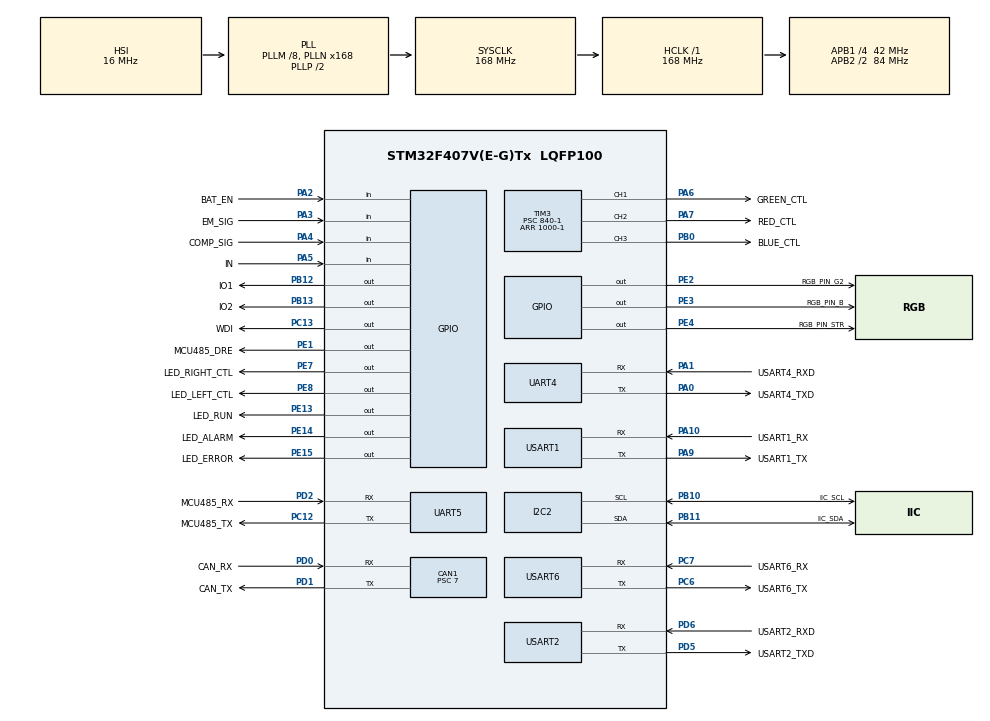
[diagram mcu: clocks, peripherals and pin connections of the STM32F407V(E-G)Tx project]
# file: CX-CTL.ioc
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CAN1.BS1=CAN_BS1_9TQ
CAN1.BS2=CAN_BS2_2TQ
CAN1.CalculateBaudRate=499999
CAN1.CalculateTimeBit=2000
CAN1.CalculateTimeQuantum=166.66666666666669
CAN1.Prescaler=7
Dma.Request0=UART4_TX
Dma.Request1=UART4_RX
Dma.Request2=UART5_RX
Dma.Request3=UART5_TX
Dma.Request4=USART1_RX
Dma.Request5=USART1_TX
Dma.Request6=USART2_RX
Dma.Request7=USART2_TX
Dma.Request8=USART6_RX
Dma.Request9=USART6_TX
Dma.UART4_RX.1.Direction=DMA_PERIPH_TO_MEMORY
Dma.UART4_RX.1.FIFOMode=DMA_FIFOMODE_DISABLE
Dma.UART4_RX.1.Instance=DMA1_Stream2
Dma.UART4_RX.1.MemDataAlignment=DMA_MDATAALIGN_BYTE
Dma.UART4_RX.1.MemInc=DMA_MINC_ENABLE
Dma.UART4_RX.1.Mode=DMA_NORMAL
Dma.UART4_RX.1.PeriphDataAlignment=DMA_PDATAALIGN_BYTE
Dma.UART4_RX.1.PeriphInc=DMA_PINC_DISABLE
Dma.UART4_RX.1.Priority=DMA_PRIORITY_LOW
Dma.UART4_TX.0.Direction=DMA_MEMORY_TO_PERIPH
Dma.UART4_TX.0.FIFOMode=DMA_FIFOMODE_DISABLE
Dma.UART4_TX.0.Instance=DMA1_Stream4
Dma.UART4_TX.0.MemDataAlignment=DMA_MDATAALIGN_BYTE
Dma.UART4_TX.0.MemInc=DMA_MINC_ENABLE
Dma.UART4_TX.0.Mode=DMA_NORMAL
Dma.UART4_TX.0.PeriphDataAlignment=DMA_PDATAALIGN_BYTE
Dma.UART4_TX.0.PeriphInc=DMA_PINC_DISABLE
Dma.UART4_TX.0.Priority=DMA_PRIORITY_LOW
Dma.UART5_RX.2.Direction=DMA_PERIPH_TO_MEMORY
Dma.UART5_RX.2.FIFOMode=DMA_FIFOMODE_DISABLE
Dma.UART5_RX.2.Instance=DMA1_Stream0
Dma.UART5_RX.2.MemDataAlignment=DMA_MDATAALIGN_BYTE
Dma.UART5_RX.2.MemInc=DMA_MINC_ENABLE
Dma.UART5_RX.2.Mode=DMA_NORMAL
Dma.UART5_RX.2.PeriphDataAlignment=DMA_PDATAALIGN_BYTE
Dma.UART5_RX.2.PeriphInc=DMA_PINC_DISABLE
Dma.UART5_RX.2.Priority=DMA_PRIORITY_LOW
Dma.UART5_TX.3.Direction=DMA_MEMORY_TO_PERIPH
Dma.UART5_TX.3.FIFOMode=DMA_FIFOMODE_DISABLE
Dma.UART5_TX.3.Instance=DMA1_Stream7
Dma.UART5_TX.3.MemDataAlignment=DMA_MDATAALIGN_BYTE
Dma.UART5_TX.3.MemInc=DMA_MINC_ENABLE
Dma.UART5_TX.3.Mode=DMA_NORMAL
Dma.UART5_TX.3.PeriphDataAlignment=DMA_PDATAALIGN_BYTE
Dma.UART5_TX.3.PeriphInc=DMA_PINC_DISABLE
Dma.UART5_TX.3.Priority=DMA_PRIORITY_LOW
Dma.USART1_RX.4.Direction=DMA_PERIPH_TO_MEMORY
Dma.USART1_RX.4.FIFOMode=DMA_FIFOMODE_DISABLE
Dma.USART1_RX.4.Instance=DMA2_Stream2
Dma.USART1_RX.4.MemDataAlignment=DMA_MDATAALIGN_BYTE
Dma.USART1_RX.4.MemInc=DMA_MINC_ENABLE
Dma.USART1_RX.4.Mode=DMA_NORMAL
Dma.USART1_RX.4.PeriphDataAlignment=DMA_PDATAALIGN_BYTE
Dma.USART1_RX.4.PeriphInc=DMA_PINC_DISABLE
Dma.USART1_RX.4.Priority=DMA_PRIORITY_LOW
Dma.USART1_TX.5.Direction=DMA_MEMORY_TO_PERIPH
Dma.USART1_TX.5.FIFOMode=DMA_FIFOMODE_DISABLE
Dma.USART1_TX.5.Instance=DMA2_Stream7
Dma.USART1_TX.5.MemDataAlignment=DMA_MDATAALIGN_BYTE
Dma.USART1_TX.5.MemInc=DMA_MINC_ENABLE
Dma.USART1_TX.5.Mode=DMA_NORMAL
Dma.USART1_TX.5.PeriphDataAlignment=DMA_PDATAALIGN_BYTE
Dma.USART1_TX.5.PeriphInc=DMA_PINC_DISABLE
Dma.USART1_TX.5.Priority=DMA_PRIORITY_LOW
Dma.USART2_RX.6.Direction=DMA_PERIPH_TO_MEMORY
Dma.USART2_RX.6.FIFOMode=DMA_FIFOMODE_DISABLE
Dma.USART2_RX.6.Instance=DMA1_Stream5
Dma.USART2_RX.6.MemDataAlignment=DMA_MDATAALIGN_BYTE
Dma.USART2_RX.6.MemInc=DMA_MINC_ENABLE
Dma.USART2_RX.6.Mode=DMA_NORMAL
Dma.USART2_RX.6.PeriphDataAlignment=DMA_PDATAALIGN_BYTE
Dma.USART2_RX.6.PeriphInc=DMA_PINC_DISABLE
Dma.USART2_RX.6.Priority=DMA_PRIORITY_LOW
Dma.USART2_TX.7.Direction=DMA_MEMORY_TO_PERIPH
Dma.USART2_TX.7.FIFOMode=DMA_FIFOMODE_DISABLE
Dma.USART2_TX.7.Instance=DMA1_Stream6
Dma.USART2_TX.7.MemDataAlignment=DMA_MDATAALIGN_BYTE
Dma.USART2_TX.7.MemInc=DMA_MINC_ENABLE
Dma.USART2_TX.7.Mode=DMA_NORMAL
Dma.USART2_TX.7.PeriphDataAlignment=DMA_PDATAALIGN_BYTE
Dma.USART2_TX.7.PeriphInc=DMA_PINC_DISABLE
Dma.USART2_TX.7.Priority=DMA_PRIORITY_LOW
Dma.USART6_RX.8.Direction=DMA_PERIPH_TO_MEMORY
Dma.USART6_RX.8.FIFOMode=DMA_FIFOMODE_DISABLE
Dma.USART6_RX.8.Instance=DMA2_Stream1
Dma.USART6_RX.8.MemDataAlignment=DMA_MDATAALIGN_BYTE
Dma.USART6_RX.8.MemInc=DMA_MINC_ENABLE
Dma.USART6_RX.8.Mode=DMA_NORMAL
Dma.USART6_RX.8.PeriphDataAlignment=DMA_PDATAALIGN_BYTE
Dma.USART6_RX.8.PeriphInc=DMA_PINC_DISABLE
Dma.USART6_RX.8.Priority=DMA_PRIORITY_LOW
Dma.USART6_TX.9.Direction=DMA_MEMORY_TO_PERIPH
Dma.USART6_TX.9.FIFOMode=DMA_FIFOMODE_DISABLE
Dma.USART6_TX.9.Instance=DMA2_Stream6
Dma.USART6_TX.9.MemDataAlignment=DMA_MDATAALIGN_BYTE
Dma.USART6_TX.9.MemInc=DMA_MINC_ENABLE
Dma.USART6_TX.9.Mode=DMA_NORMAL
Dma.USART6_TX.9.PeriphDataAlignment=DMA_PDATAALIGN_BYTE
Dma.USART6_TX.9.PeriphInc=DMA_PINC_DISABLE
Dma.USART6_TX.9.Priority=DMA_PRIORITY_LOW
FREERTOS.Mutexes01=AppPrintfMutex,Dynamic,NULL;AppVelocityMutex,Dynamic,NULL
FREERTOS.Queues01=RS485TxQueue,10,uint32_t,0,Dynamic,NULL,NULL;RS485RxQueue,10,uint32_t,0,Dynamic,NULL,NULL;USART1TxQueue,10,uint32_t,0,Dynamic,NULL,NULL;USART1RxQueue,10,uint32_t,0,Dynamic,NULL,NULL;USART2TxQueue,10,uint32_t,0,Dynamic,NULL,NULL;USART4TxQueue,10,uint32_t,0,Dynamic,NULL,NULL;USART4RxQueue,10,uint32_t,0,Dynamic,NULL,NULL;USART6TxQueue,10,uint32_t,0,Dynamic,NULL,NULL;USART6RxQueue,10,uint32_t,0,Dynamic,NULL,NULL;USART2RxQueue,10,uint32_t,0,Dynamic,NULL,NULL;CAN1TxQueue,10,uint32_t,0,Dynamic,NULL,NULL
FREERTOS.Tasks01=TaskSysInit,40,512,StartTaskSYSInit,As weak,NULL,Dynamic,NULL,NULL;ledTask,24,128,StartTaskLed,As weak,NULL,Dynamic,NULL,NULL;canTask,40,512,StartTaskCan,As weak,NULL,Dynamic,NULL,NULL;watchdogTask,24,128,StartTaskWatchdog,As weak,NULL,Dynamic,NULL,NULL;rs232Task,24,128,StartTaskRS232,As weak,NULL,Dynamic,NULL,NULL;rs485Task,24,128,StartTaskRS485,As weak,NULL,Dynamic,NULL,NULL;serialTask,24,128,StartTaskSerial,As weak,NULL,Dynamic,NULL,NULL;motionTask,48,512,StartTaskMotion,As weak,NULL,Dynamic,NULL,NULL
Mcu.Family=STM32F4
Mcu.Name=STM32F407V(E-G)Tx
Mcu.Package=LQFP100
NVIC.CAN1_RX0_IRQn=true\:5\:0\:false\:false\:true\:true\:true\:true\:true
NVIC.DMA1_Stream0_IRQn=true\:5\:0\:false\:false\:true\:true\:false\:true\:true
NVIC.DMA1_Stream2_IRQn=true\:5\:0\:false\:false\:true\:true\:false\:true\:true
NVIC.DMA1_Stream4_IRQn=true\:5\:0\:false\:false\:true\:true\:false\:true\:true
NVIC.DMA1_Stream5_IRQn=true\:5\:0\:false\:false\:true\:true\:false\:true\:true
NVIC.DMA1_Stream6_IRQn=true\:5\:0\:false\:false\:true\:true\:false\:true\:true
NVIC.DMA1_Stream7_IRQn=true\:5\:0\:false\:false\:true\:true\:false\:true\:true
NVIC.DMA2_Stream1_IRQn=true\:5\:0\:false\:false\:true\:true\:false\:true\:true
NVIC.DMA2_Stream2_IRQn=true\:5\:0\:false\:false\:true\:true\:false\:true\:true
NVIC.DMA2_Stream6_IRQn=true\:5\:0\:false\:false\:true\:true\:false\:true\:true
NVIC.DMA2_Stream7_IRQn=true\:5\:0\:false\:false\:true\:true\:false\:true\:true
NVIC.I2C2_ER_IRQn=true\:5\:0\:false\:false\:true\:true\:true\:true\:true
NVIC.I2C2_EV_IRQn=true\:5\:0\:false\:false\:true\:true\:true\:true\:true
NVIC.PriorityGroup=NVIC_PRIORITYGROUP_4
NVIC.TIM2_IRQn=true\:5\:0\:false\:false\:true\:true\:true\:true\:true
NVIC.TIM3_IRQn=true\:5\:0\:false\:false\:true\:true\:true\:true\:true
NVIC.TIM4_IRQn=true\:5\:0\:false\:false\:true\:true\:true\:true\:true
NVIC.TIM5_IRQn=true\:5\:0\:false\:false\:true\:true\:true\:true\:true
NVIC.UART4_IRQn=true\:5\:0\:false\:false\:true\:true\:true\:true\:true
NVIC.UART5_IRQn=true\:5\:0\:false\:false\:true\:true\:true\:true\:true
NVIC.USART1_IRQn=true\:5\:0\:false\:false\:true\:true\:true\:true\:true
NVIC.USART2_IRQn=true\:5\:0\:false\:false\:true\:true\:true\:true\:true
NVIC.USART6_IRQn=true\:5\:0\:false\:false\:true\:true\:true\:true\:true
PA0-WKUP.GPIO_Label=USART4_TXD
PA0-WKUP.GPIO_PuPd=GPIO_PULLUP
PA0-WKUP.Mode=Asynchronous
PA0-WKUP.Signal=UART4_TX
PA1.GPIO_Label=USART4_RXD
PA1.GPIO_PuPd=GPIO_PULLUP
PA1.Mode=Asynchronous
PA1.Signal=UART4_RX
PA10.GPIO_Label=USART1_RX
PA10.GPIO_PuPd=GPIO_PULLUP
PA10.Mode=Asynchronous
PA10.Signal=USART1_RX
PA13.GPIO_Label=SWDIO
PA13.Mode=Serial_Wire
PA13.Signal=SYS_JTMS-SWDIO
PA14.GPIO_Label=SWCLK
PA14.Mode=Serial_Wire
PA14.Signal=SYS_JTCK-SWCLK
PA2.GPIO_Label=BAT_EN
PA2.GPIO_PuPd=GPIO_PULLUP
PA2.Signal=GPIO_Input
PA3.GPIO_Label=EM_SIG
PA3.GPIO_PuPd=GPIO_PULLUP
PA3.Signal=GPIO_Input
PA4.GPIO_Label=COMP_SIG
PA4.GPIO_PuPd=GPIO_PULLUP
PA4.Signal=GPIO_Input
PA5.GPIO_Label=IN
PA5.GPIO_PuPd=GPIO_PULLUP
PA5.Signal=GPIO_Input
PA6.GPIO_Label=GREEN_CTL
PA6.GPIO_PuPd=GPIO_PULLUP
PA6.Signal=S_TIM3_CH1
PA7.GPIO_Label=RED_CTL
PA7.GPIO_PuPd=GPIO_PULLUP
PA7.Signal=S_TIM3_CH2
PA9.GPIO_Label=USART1_TX
PA9.GPIO_PuPd=GPIO_PULLUP
PA9.Mode=Asynchronous
PA9.Signal=USART1_TX
PB0.GPIO_Label=BLUE_CTL
PB0.GPIO_PuPd=GPIO_PULLUP
PB0.Signal=S_TIM3_CH3
PB10.GPIO_Label=IIC_SCL
PB10.GPIO_Pu=GPIO_PULLUP
PB10.Mode=I2C
PB10.Signal=I2C2_SCL
PB11.GPIO_Label=IIC_SDA
PB11.GPIO_Pu=GPIO_PULLUP
PB11.Mode=I2C
PB11.Signal=I2C2_SDA
PB12.GPIO_Label=IO1
PB12.GPIO_Speed=GPIO_SPEED_FREQ_VERY_HIGH
PB12.Signal=GPIO_Output
PB13.GPIO_Label=IO2
PB13.GPIO_Speed=GPIO_SPEED_FREQ_VERY_HIGH
PB13.Signal=GPIO_Output
PC12.GPIO_Label=MCU485_TX
PC12.GPIO_PuPd=GPIO_PULLUP
PC12.Mode=Asynchronous
PC12.Signal=UART5_TX
PC13-ANTI_TAMP.GPIO_Label=WDI
PC13-ANTI_TAMP.GPIO_PuPd=GPIO_PULLUP
PC13-ANTI_TAMP.Signal=GPIO_Output
PC6.GPIO_Label=USART6_TX
PC6.GPIO_PuPd=GPIO_PULLUP
PC6.Mode=Asynchronous
PC6.Signal=USART6_TX
PC7.GPIO_Label=USART6_RX
PC7.GPIO_PuPd=GPIO_PULLUP
PC7.Mode=Asynchronous
PC7.Signal=USART6_RX
PD0.GPIO_Label=CAN_RX
PD0.GPIO_PuPd=GPIO_PULLUP
PD0.Mode=CAN_Activate
PD0.Signal=CAN1_RX
PD1.GPIO_Label=CAN_TX
PD1.GPIO_PuPd=GPIO_PULLUP
PD1.Mode=CAN_Activate
PD1.Signal=CAN1_TX
PD2.GPIO_Label=MCU485_RX
PD2.GPIO_PuPd=GPIO_PULLUP
PD2.Mode=Asynchronous
PD2.Signal=UART5_RX
PD5.GPIO_Label=USART2_TXD
PD5.GPIO_PuPd=GPIO_PULLUP
PD5.Mode=Asynchronous
PD5.Signal=USART2_TX
PD6.GPIO_Label=USART2_RXD
PD6.GPIO_PuPd=GPIO_PULLUP
PD6.Mode=Asynchronous
PD6.Signal=USART2_RX
PE1.GPIO_Label=MCU485_DRE
PE1.GPIO_PuPd=GPIO_PULLUP
PE1.GPIO_Speed=GPIO_SPEED_FREQ_VERY_HIGH
PE1.Signal=GPIO_Output
PE13.GPIO_Label=LED_RUN
PE13.GPIO_PuPd=GPIO_PULLUP
PE13.GPIO_Speed=GPIO_SPEED_FREQ_VERY_HIGH
PE13.Signal=GPIO_Output
PE14.GPIO_Label=LED_ALARM
PE14.GPIO_PuPd=GPIO_PULLUP
PE14.GPIO_Speed=GPIO_SPEED_FREQ_VERY_HIGH
PE14.Signal=GPIO_Output
PE15.GPIO_Label=LED_ERROR
PE15.GPIO_PuPd=GPIO_PULLUP
PE15.GPIO_Speed=GPIO_SPEED_FREQ_VERY_HIGH
PE15.Signal=GPIO_Output
PE2.GPIO_Label=RGB_PIN_G2
PE2.GPIO_PuPd=GPIO_PULLUP
PE2.GPIO_Speed=GPIO_SPEED_FREQ_VERY_HIGH
PE2.Signal=GPIO_Output
PE3.GPIO_Label=RGB_PIN_B
PE3.GPIO_PuPd=GPIO_PULLUP
PE3.GPIO_Speed=GPIO_SPEED_FREQ_VERY_HIGH
PE3.Signal=GPIO_Output
PE4.GPIO_Label=RGB_PIN_STR
PE4.GPIO_PuPd=GPIO_PULLUP
PE4.GPIO_Speed=GPIO_SPEED_FREQ_VERY_HIGH
PE4.Signal=GPIO_Output
PE7.GPIO_Label=LED_RIGHT_CTL
PE7.GPIO_Speed=GPIO_SPEED_FREQ_VERY_HIGH
PE7.Signal=GPIO_Output
PE8.GPIO_Label=LED_LEFT_CTL
PE8.GPIO_PuPd=GPIO_PULLUP
PE8.GPIO_Speed=GPIO_SPEED_FREQ_VERY_HIGH
PE8.Signal=GPIO_Output
PH0-OSC_IN.Mode=HSE-External-Oscillator
PH0-OSC_IN.Signal=RCC_OSC_IN
PH1-OSC_OUT.Mode=HSE-External-Oscillator
PH1-OSC_OUT.Signal=RCC_OSC_OUT
ProjectManager.HeapSize=0x200
ProjectManager.StackSize=0x400
ProjectManager.TargetToolchain=MDK-ARM V5.32
RCC.48MHZClocksFreq_Value=84000000
RCC.AHBFreq_Value=168000000
RCC.APB1CLKDivider=RCC_HCLK_DIV4
RCC.APB1Freq_Value=42000000
RCC.APB1TimFreq_Value=84000000
RCC.APB2CLKDivider=RCC_HCLK_DIV2
RCC.APB2Freq_Value=84000000
RCC.APB2TimFreq_Value=168000000
RCC.CortexFreq_Value=168000000
RCC.HCLKFreq_Value=168000000
RCC.HSE_VALUE=8000000
RCC.HSI_VALUE=16000000
RCC.LSE_VALUE=32768
RCC.PLLM=8
RCC.PLLN=168
RCC.SYSCLKFreq_VALUE=168000000
RCC.SYSCLKSource=RCC_SYSCLKSOURCE_PLLCLK
RCC.VCOOutputFreq_Value=336000000
SH.S_TIM3_CH1.0=TIM3_CH1,PWM Generation1 CH1
SH.S_TIM3_CH2.0=TIM3_CH2,PWM Generation2 CH2
SH.S_TIM3_CH3.0=TIM3_CH3,PWM Generation3 CH3
TIM2.Period=50
TIM2.Prescaler=8400-1
TIM3.Channel-PWM\ Generation1\ CH1=TIM_CHANNEL_1
TIM3.Channel-PWM\ Generation2\ CH2=TIM_CHANNEL_2
TIM3.Channel-PWM\ Generation3\ CH3=TIM_CHANNEL_3
TIM3.Period=1000-1
TIM3.Prescaler=840-1
TIM4.Channel-Output\ Compare1\ No\ Output=TIM_CHANNEL_1
TIM4.Period=1000-1
TIM4.Prescaler=84-1
TIM5.Period=1000
TIM5.Prescaler=840-1
UART4.VirtualMode=Asynchronous
UART5.VirtualMode=Asynchronous
USART1.VirtualMode=VM_ASYNC
USART2.VirtualMode=VM_ASYNC
USART6.VirtualMode=VM_ASYNC
VP_FREERTOS_VS_CMSIS_V2.Mode=CMSIS_V2
VP_TIM2_VS_ClockSourceINT.Mode=Internal
VP_TIM3_VS_ClockSourceINT.Mode=Internal
VP_TIM4_VS_no_output1.Mode=Output Compare1 No Output
VP_TIM5_VS_ClockSourceINT.Mode=Internal
board=custom

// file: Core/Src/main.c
/* USER CODE BEGIN Header */
/**
  ******************************************************************************
  * @file           : main.c
  * @brief          : Main program body
  ******************************************************************************
  * @attention
  *
  * Copyright (c) 2022 STMicroelectronics.
  * All rights reserved.
  *
  * This software is licensed under terms that can be found in the LICENSE file
  * in the root directory of this software component.
  * If no LICENSE file comes with this software, it is provided AS-IS.
  *
  ******************************************************************************
  */
/* USER CODE END Header */
#include "main.h"
#include "cmsis_os.h"
#include "can.h"
#include "dma.h"
#include "i2c.h"
#include "tim.h"
#include "usart.h"
#include "gpio.h"

void SystemClock_Config(void);
void MX_FREERTOS_Init(void);

int main(void)
{

  /* MCU Configuration--------------------------------------------------------*/

  /* Reset of all peripherals, Initializes the Flash interface and the Systick. */
  HAL_Init();

  /* Configure the system clock */
  SystemClock_Config();

  /* Initialize all configured peripherals */
  MX_GPIO_Init();
  MX_DMA_Init();
  MX_CAN1_Init();
  MX_I2C2_Init();
  MX_TIM2_Init();
  MX_TIM3_Init();
  MX_TIM4_Init();
  MX_TIM5_Init();
  MX_UART4_Init();
  MX_UART5_Init();
  MX_USART1_UART_Init();
  MX_USART2_UART_Init();
  MX_USART6_UART_Init();

  /* Init scheduler */
  osKernelInitialize();  /* Call init function for freertos objects (in freertos.c) */
  MX_FREERTOS_Init();

  /* Start scheduler */
  osKernelStart();

  /* We should never get here as control is now taken by the scheduler */
  /* Infinite loop */
  while (1)
  {

  }
}

void SystemClock_Config(void)
{
  RCC_OscInitTypeDef RCC_OscInitStruct = {0};
  RCC_ClkInitTypeDef RCC_ClkInitStruct = {0};

  /** Configure the main internal regulator output voltage
  */
  __HAL_RCC_PWR_CLK_ENABLE();
  __HAL_PWR_VOLTAGESCALING_CONFIG(PWR_REGULATOR_VOLTAGE_SCALE1);

  /** Initializes the RCC Oscillators according to the specified parameters
  * in the RCC_OscInitTypeDef structure.
  */
  RCC_OscInitStruct.OscillatorType = RCC_OSCILLATORTYPE_HSI;
  RCC_OscInitStruct.HSIState = RCC_HSI_ON;
  RCC_OscInitStruct.HSICalibrationValue = RCC_HSICALIBRATION_DEFAULT;
  RCC_OscInitStruct.PLL.PLLState = RCC_PLL_ON;
  RCC_OscInitStruct.PLL.PLLSource = RCC_PLLSOURCE_HSI;
  RCC_OscInitStruct.PLL.PLLM = 8;
  RCC_OscInitStruct.PLL.PLLN = 168;
  RCC_OscInitStruct.PLL.PLLP = RCC_PLLP_DIV2;
  RCC_OscInitStruct.PLL.PLLQ = 4;
  if (HAL_RCC_OscConfig(&RCC_OscInitStruct) != HAL_OK)
  {
    Error_Handler();
  }

  /** Initializes the CPU, AHB and APB buses clocks
  */
  RCC_ClkInitStruct.ClockType = RCC_CLOCKTYPE_HCLK|RCC_CLOCKTYPE_SYSCLK
                              |RCC_CLOCKTYPE_PCLK1|RCC_CLOCKTYPE_PCLK2;
  RCC_ClkInitStruct.SYSCLKSource = RCC_SYSCLKSOURCE_PLLCLK;
  RCC_ClkInitStruct.AHBCLKDivider = RCC_SYSCLK_DIV1;
  RCC_ClkInitStruct.APB1CLKDivider = RCC_HCLK_DIV4;
  RCC_ClkInitStruct.APB2CLKDivider = RCC_HCLK_DIV2;

  if (HAL_RCC_ClockConfig(&RCC_ClkInitStruct, FLASH_LATENCY_5) != HAL_OK)
  {
    Error_Handler();
  }
}

void Error_Handler(void)
{
  __disable_irq();
  while (1)
  {
  }
}

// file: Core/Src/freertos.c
/* USER CODE BEGIN Header */
/**
  ******************************************************************************
  * File Name          : freertos.c
  * Description        : Code for freertos applications
  ******************************************************************************
  * @attention
  *
  * Copyright (c) 2022 STMicroelectronics.
  * All rights reserved.
  *
  * This software is licensed under terms that can be found in the LICENSE file
  * in the root directory of this software component.
  * If no LICENSE file comes with this software, it is provided AS-IS.
  *
  ******************************************************************************
  */
/* USER CODE END Header */

#include "FreeRTOS.h"
#include "task.h"
#include "main.h"
#include "cmsis_os.h"

/* USER CODE BEGIN Variables */
volatile unsigned long ulHighFrequencyTimerTicks;
/* USER CODE END Variables */
/* Definitions for TaskSysInit */
osThreadId_t TaskSysInitHandle;
const osThreadAttr_t TaskSysInit_attributes = {
  .name = "TaskSysInit",
  .stack_size = 512 * 4,
  .priority = (osPriority_t) osPriorityHigh,
};
/* Definitions for ledTask */
osThreadId_t ledTaskHandle;
const osThreadAttr_t ledTask_attributes = {
  .name = "ledTask",
  .stack_size = 128 * 4,
  .priority = (osPriority_t) osPriorityNormal,
};
/* Definitions for canTask */
osThreadId_t canTaskHandle;
const osThreadAttr_t canTask_attributes = {
  .name = "canTask",
  .stack_size = 512 * 4,
  .priority = (osPriority_t) osPriorityHigh,
};
/* Definitions for watchdogTask */
osThreadId_t watchdogTaskHandle;
const osThreadAttr_t watchdogTask_attributes = {
  .name = "watchdogTask",
  .stack_size = 128 * 4,
  .priority = (osPriority_t) osPriorityNormal,
};
/* Definitions for rs232Task */
osThreadId_t rs232TaskHandle;
const osThreadAttr_t rs232Task_attributes = {
  .name = "rs232Task",
  .stack_size = 128 * 4,
  .priority = (osPriority_t) osPriorityNormal,
};
/* Definitions for rs485Task */
osThreadId_t rs485TaskHandle;
const osThreadAttr_t rs485Task_attributes = {
  .name = "rs485Task",
  .stack_size = 128 * 4,
  .priority = (osPriority_t) osPriorityNormal,
};
/* Definitions for serialTask */
osThreadId_t serialTaskHandle;
const osThreadAttr_t serialTask_attributes = {
  .name = "serialTask",
  .stack_size = 128 * 4,
  .priority = (osPriority_t) osPriorityNormal,
};
/* Definitions for motionTask */
osThreadId_t motionTaskHandle;
const osThreadAttr_t motionTask_attributes = {
  .name = "motionTask",
  .stack_size = 512 * 4,
  .priority = (osPriority_t) osPriorityRealtime,
};
/* Definitions for RS485TxQueue */
osMessageQueueId_t RS485TxQueueHandle;
const osMessageQueueAttr_t RS485TxQueue_attributes = {
  .name = "RS485TxQueue"
};
/* Definitions for RS485RxQueue */
osMessageQueueId_t RS485RxQueueHandle;
const osMessageQueueAttr_t RS485RxQueue_attributes = {
  .name = "RS485RxQueue"
};
/* Definitions for USART1TxQueue */
osMessageQueueId_t USART1TxQueueHandle;
const osMessageQueueAttr_t USART1TxQueue_attributes = {
  .name = "USART1TxQueue"
};
/* Definitions for USART1RxQueue */
osMessageQueueId_t USART1RxQueueHandle;
const osMessageQueueAttr_t USART1RxQueue_attributes = {
  .name = "USART1RxQueue"
};
/* Definitions for USART2TxQueue */
osMessageQueueId_t USART2TxQueueHandle;
const osMessageQueueAttr_t USART2TxQueue_attributes = {
  .name = "USART2TxQueue"
};
/* Definitions for USART4TxQueue */
osMessageQueueId_t USART4TxQueueHandle;
const osMessageQueueAttr_t USART4TxQueue_attributes = {
  .name = "USART4TxQueue"
};
/* Definitions for USART4RxQueue */
osMessageQueueId_t USART4RxQueueHandle;
const osMessageQueueAttr_t USART4RxQueue_attributes = {
  .name = "USART4RxQueue"
};
/* Definitions for USART6TxQueue */
osMessageQueueId_t USART6TxQueueHandle;
const osMessageQueueAttr_t USART6TxQueue_attributes = {
  .name = "USART6TxQueue"
};
/* Definitions for USART6RxQueue */
osMessageQueueId_t USART6RxQueueHandle;
const osMessageQueueAttr_t USART6RxQueue_attributes = {
  .name = "USART6RxQueue"
};
/* Definitions for USART2RxQueue */
osMessageQueueId_t USART2RxQueueHandle;
const osMessageQueueAttr_t USART2RxQueue_attributes = {
  .name = "USART2RxQueue"
};
/* Definitions for CAN1TxQueue */
osMessageQueueId_t CAN1TxQueueHandle;
const osMessageQueueAttr_t CAN1TxQueue_attributes = {
  .name = "CAN1TxQueue"
};
/* Definitions for AppPrintfMutex */
osMutexId_t AppPrintfMutexHandle;
const osMutexAttr_t AppPrintfMutex_attributes = {
  .name = "AppPrintfMutex"
};
/* Definitions for AppVelocityMutex */
osMutexId_t AppVelocityMutexHandle;
const osMutexAttr_t AppVelocityMutex_attributes = {
  .name = "AppVelocityMutex"
};

/* USER CODE BEGIN FunctionPrototypes */
osMessageQueueId_t SysErrorQueueHandle;
const osMessageQueueAttr_t SysErrorQueue_attributes = {
  .name = "SysErrorQueue"
};
/* USER CODE END FunctionPrototypes */

void StartTaskSYSInit(void *argument);
void StartTaskLed(void *argument);
void StartTaskCan(void *argument);
void StartTaskWatchdog(void *argument);
void StartTaskRS232(void *argument);
void StartTaskRS485(void *argument);
void StartTaskSerial(void *argument);
void StartTaskMotion(void *argument);

void MX_FREERTOS_Init(void); /* (MISRA C 2004 rule 8.1) */

void MX_FREERTOS_Init(void) {
  /* Create the mutex(es) */
  /* creation of AppPrintfMutex */
  AppPrintfMutexHandle = osMutexNew(&AppPrintfMutex_attributes);

  /* creation of AppVelocityMutex */
  AppVelocityMutexHandle = osMutexNew(&AppVelocityMutex_attributes);

  /* Create the queue(s) */
  /* creation of RS485TxQueue */
  RS485TxQueueHandle = osMessageQueueNew (10, sizeof(uint32_t), &RS485TxQueue_attributes);

  /* creation of RS485RxQueue */
  RS485RxQueueHandle = osMessageQueueNew (10, sizeof(uint32_t), &RS485RxQueue_attributes);

  /* creation of USART1TxQueue */
  USART1TxQueueHandle = osMessageQueueNew (10, sizeof(uint32_t), &USART1TxQueue_attributes);

  /* creation of USART1RxQueue */
  USART1RxQueueHandle = osMessageQueueNew (10, sizeof(uint32_t), &USART1RxQueue_attributes);

  /* creation of USART2TxQueue */
  USART2TxQueueHandle = osMessageQueueNew (10, sizeof(uint32_t), &USART2TxQueue_attributes);

  /* creation of USART4TxQueue */
  USART4TxQueueHandle = osMessageQueueNew (10, sizeof(uint32_t), &USART4TxQueue_attributes);

  /* creation of USART4RxQueue */
  USART4RxQueueHandle = osMessageQueueNew (10, sizeof(uint32_t), &USART4RxQueue_attributes);

  /* creation of USART6TxQueue */
  USART6TxQueueHandle = osMessageQueueNew (10, sizeof(uint32_t), &USART6TxQueue_attributes);

  /* creation of USART6RxQueue */
  USART6RxQueueHandle = osMessageQueueNew (10, sizeof(uint32_t), &USART6RxQueue_attributes);

  /* creation of USART2RxQueue */
  USART2RxQueueHandle = osMessageQueueNew (10, sizeof(uint32_t), &USART2RxQueue_attributes);

  /* creation of CAN1TxQueue */
  CAN1TxQueueHandle = osMessageQueueNew (10, sizeof(uint32_t), &CAN1TxQueue_attributes);

  /* USER CODE BEGIN RTOS_QUEUES */
  /* add queues, ... */
  SysErrorQueueHandle = osMessageQueueNew (10, sizeof(uint32_t), &SysErrorQueue_attributes);
  /* USER CODE END RTOS_QUEUES */

  /* Create the thread(s) */
  /* creation of TaskSysInit */
  TaskSysInitHandle = osThreadNew(StartTaskSYSInit, NULL, &TaskSysInit_attributes);

  /* creation of ledTask */
  ledTaskHandle = osThreadNew(StartTaskLed, NULL, &ledTask_attributes);

  /* creation of canTask */
  canTaskHandle = osThreadNew(StartTaskCan, NULL, &canTask_attributes);

  /* creation of watchdogTask */
  watchdogTaskHandle = osThreadNew(StartTaskWatchdog, NULL, &watchdogTask_attributes);

  /* creation of rs232Task */
  rs232TaskHandle = osThreadNew(StartTaskRS232, NULL, &rs232Task_attributes);

  /* creation of rs485Task */
  rs485TaskHandle = osThreadNew(StartTaskRS485, NULL, &rs485Task_attributes);

  /* creation of serialTask */
  serialTaskHandle = osThreadNew(StartTaskSerial, NULL, &serialTask_attributes);

  /* creation of motionTask */
  motionTaskHandle = osThreadNew(StartTaskMotion, NULL, &motionTask_attributes);

}

__weak void StartTaskSYSInit(void *argument)
{
  for(;;)
  {
    osDelay(1);
  }
}

__weak void StartTaskLed(void *argument)
{
  for(;;)
  {
    osDelay(1);
  }
}

__weak void StartTaskCan(void *argument)
{
  for(;;)
  {
    osDelay(1);
  }
}

__weak void StartTaskWatchdog(void *argument)
{
  for(;;)
  {
    osDelay(1);
  }
}

__weak void StartTaskRS232(void *argument)
{
  for(;;)
  {
    osDelay(1);
  }
}

__weak void StartTaskRS485(void *argument)
{
  for(;;)
  {
    osDelay(1);
  }
}

__weak void StartTaskSerial(void *argument)
{
  for(;;)
  {
    osDelay(1);
  }
}

__weak void StartTaskMotion(void *argument)
{
  for(;;)
  {
    osDelay(1);
  }
}
